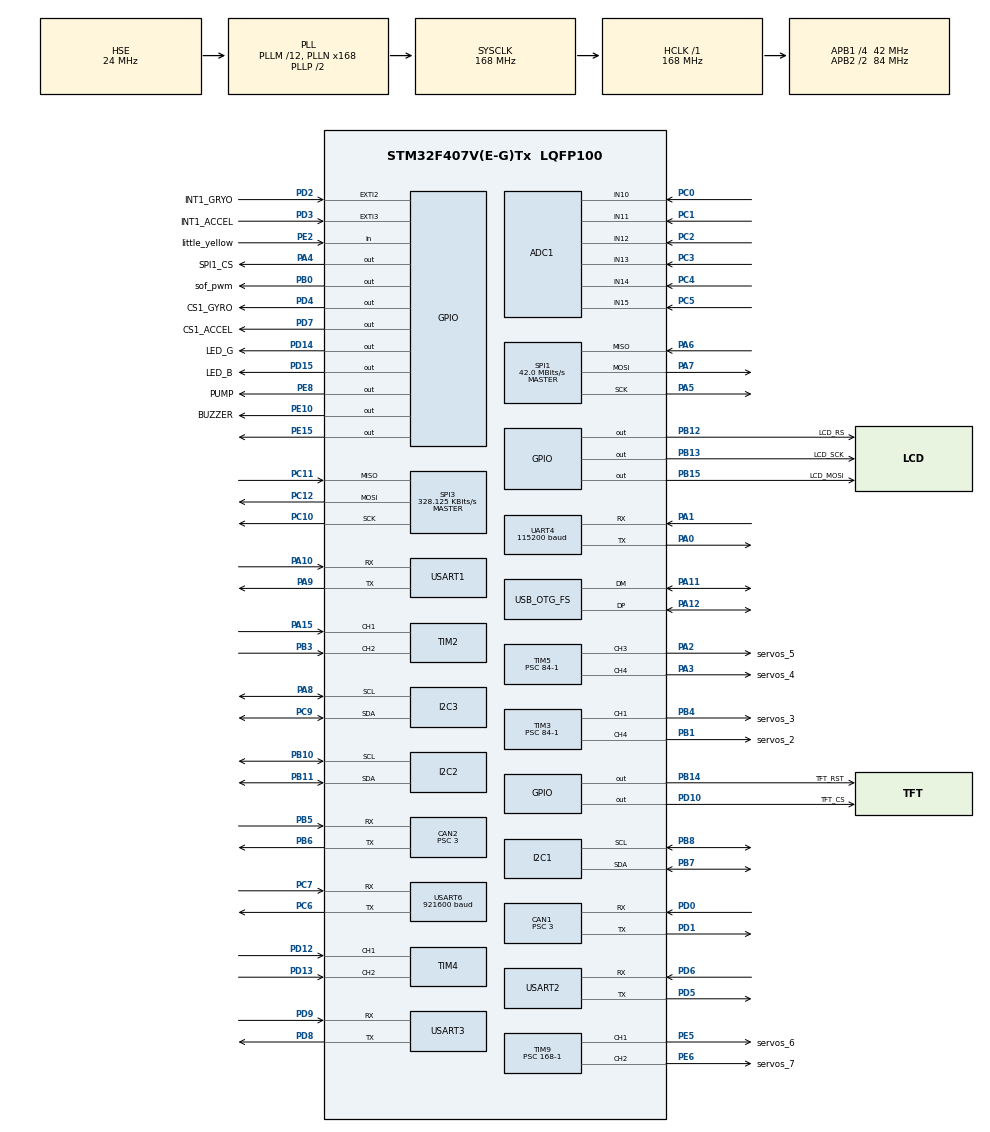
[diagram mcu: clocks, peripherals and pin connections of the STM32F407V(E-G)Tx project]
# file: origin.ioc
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ADC1.Channel-0\#ChannelRegularConversion=ADC_CHANNEL_10
ADC1.ClockPrescaler=ADC_CLOCK_SYNC_PCLK_DIV4
ADC1.NbrOfConversionFlag=1
ADC1.Rank-0\#ChannelRegularConversion=1
ADC1.SamplingTime-0\#ChannelRegularConversion=ADC_SAMPLETIME_3CYCLES
ADC1.master=1
ADC2.Channel-0\#ChannelRegularConversion=ADC_CHANNEL_10
ADC2.ClockPrescaler=ADC_CLOCK_SYNC_PCLK_DIV4
ADC2.NbrOfConversionFlag=1
ADC2.Rank-0\#ChannelRegularConversion=1
ADC2.SamplingTime-0\#ChannelRegularConversion=ADC_SAMPLETIME_3CYCLES
CAN1.BS1=CAN_BS1_10TQ
CAN1.BS2=CAN_BS2_3TQ
CAN1.CalculateBaudRate=1000000
CAN1.CalculateTimeBit=1000
CAN1.CalculateTimeQuantum=71.42857142857143
CAN1.Prescaler=3
CAN2.BS1=CAN_BS1_10TQ
CAN2.BS2=CAN_BS2_3TQ
CAN2.CalculateBaudRate=1000000
CAN2.CalculateTimeBit=1000
CAN2.CalculateTimeQuantum=71.42857142857143
CAN2.Prescaler=3
Dma.Request0=SPI3_RX
Dma.Request1=SPI3_TX
Dma.Request2=USART6_RX
Dma.Request3=USART6_TX
Dma.Request4=USART1_RX
Dma.Request5=USART1_TX
Dma.Request6=USART2_RX
Dma.Request7=USART2_TX
Dma.Request8=UART4_RX
Dma.Request9=UART4_TX
Dma.SPI3_RX.0.Direction=DMA_PERIPH_TO_MEMORY
Dma.SPI3_RX.0.FIFOMode=DMA_FIFOMODE_DISABLE
Dma.SPI3_RX.0.Instance=DMA1_Stream0
Dma.SPI3_RX.0.MemDataAlignment=DMA_MDATAALIGN_BYTE
Dma.SPI3_RX.0.MemInc=DMA_MINC_ENABLE
Dma.SPI3_RX.0.Mode=DMA_NORMAL
Dma.SPI3_RX.0.PeriphDataAlignment=DMA_PDATAALIGN_BYTE
Dma.SPI3_RX.0.PeriphInc=DMA_PINC_DISABLE
Dma.SPI3_RX.0.Priority=DMA_PRIORITY_HIGH
Dma.SPI3_TX.1.Direction=DMA_MEMORY_TO_PERIPH
Dma.SPI3_TX.1.FIFOMode=DMA_FIFOMODE_DISABLE
Dma.SPI3_TX.1.Instance=DMA1_Stream7
Dma.SPI3_TX.1.MemDataAlignment=DMA_MDATAALIGN_BYTE
Dma.SPI3_TX.1.MemInc=DMA_MINC_ENABLE
Dma.SPI3_TX.1.Mode=DMA_NORMAL
Dma.SPI3_TX.1.PeriphDataAlignment=DMA_PDATAALIGN_BYTE
Dma.SPI3_TX.1.PeriphInc=DMA_PINC_DISABLE
Dma.SPI3_TX.1.Priority=DMA_PRIORITY_MEDIUM
Dma.UART4_RX.8.Direction=DMA_PERIPH_TO_MEMORY
Dma.UART4_RX.8.FIFOMode=DMA_FIFOMODE_DISABLE
Dma.UART4_RX.8.Instance=DMA1_Stream2
Dma.UART4_RX.8.MemDataAlignment=DMA_MDATAALIGN_BYTE
Dma.UART4_RX.8.MemInc=DMA_MINC_ENABLE
Dma.UART4_RX.8.Mode=DMA_NORMAL
Dma.UART4_RX.8.PeriphDataAlignment=DMA_PDATAALIGN_BYTE
Dma.UART4_RX.8.PeriphInc=DMA_PINC_DISABLE
Dma.UART4_RX.8.Priority=DMA_PRIORITY_LOW
Dma.UART4_TX.9.Direction=DMA_MEMORY_TO_PERIPH
Dma.UART4_TX.9.FIFOMode=DMA_FIFOMODE_DISABLE
Dma.UART4_TX.9.Instance=DMA1_Stream4
Dma.UART4_TX.9.MemDataAlignment=DMA_MDATAALIGN_BYTE
Dma.UART4_TX.9.MemInc=DMA_MINC_ENABLE
Dma.UART4_TX.9.Mode=DMA_NORMAL
Dma.UART4_TX.9.PeriphDataAlignment=DMA_PDATAALIGN_BYTE
Dma.UART4_TX.9.PeriphInc=DMA_PINC_DISABLE
Dma.UART4_TX.9.Priority=DMA_PRIORITY_LOW
Dma.USART1_RX.4.Direction=DMA_PERIPH_TO_MEMORY
Dma.USART1_RX.4.FIFOMode=DMA_FIFOMODE_DISABLE
Dma.USART1_RX.4.Instance=DMA2_Stream2
Dma.USART1_RX.4.MemDataAlignment=DMA_MDATAALIGN_BYTE
Dma.USART1_RX.4.MemInc=DMA_MINC_ENABLE
Dma.USART1_RX.4.Mode=DMA_NORMAL
Dma.USART1_RX.4.PeriphDataAlignment=DMA_PDATAALIGN_BYTE
Dma.USART1_RX.4.PeriphInc=DMA_PINC_DISABLE
Dma.USART1_RX.4.Priority=DMA_PRIORITY_LOW
Dma.USART1_TX.5.Direction=DMA_MEMORY_TO_PERIPH
Dma.USART1_TX.5.FIFOMode=DMA_FIFOMODE_DISABLE
Dma.USART1_TX.5.Instance=DMA2_Stream7
Dma.USART1_TX.5.MemDataAlignment=DMA_MDATAALIGN_BYTE
Dma.USART1_TX.5.MemInc=DMA_MINC_ENABLE
Dma.USART1_TX.5.Mode=DMA_NORMAL
Dma.USART1_TX.5.PeriphDataAlignment=DMA_PDATAALIGN_BYTE
Dma.USART1_TX.5.PeriphInc=DMA_PINC_DISABLE
Dma.USART1_TX.5.Priority=DMA_PRIORITY_LOW
Dma.USART2_RX.6.Direction=DMA_PERIPH_TO_MEMORY
Dma.USART2_RX.6.FIFOMode=DMA_FIFOMODE_DISABLE
Dma.USART2_RX.6.Instance=DMA1_Stream5
Dma.USART2_RX.6.MemDataAlignment=DMA_MDATAALIGN_BYTE
Dma.USART2_RX.6.MemInc=DMA_MINC_ENABLE
Dma.USART2_RX.6.Mode=DMA_NORMAL
Dma.USART2_RX.6.PeriphDataAlignment=DMA_PDATAALIGN_BYTE
Dma.USART2_RX.6.PeriphInc=DMA_PINC_DISABLE
Dma.USART2_RX.6.Priority=DMA_PRIORITY_LOW
Dma.USART2_TX.7.Direction=DMA_MEMORY_TO_PERIPH
Dma.USART2_TX.7.FIFOMode=DMA_FIFOMODE_DISABLE
Dma.USART2_TX.7.Instance=DMA1_Stream6
Dma.USART2_TX.7.MemDataAlignment=DMA_MDATAALIGN_BYTE
Dma.USART2_TX.7.MemInc=DMA_MINC_ENABLE
Dma.USART2_TX.7.Mode=DMA_NORMAL
Dma.USART2_TX.7.PeriphDataAlignment=DMA_PDATAALIGN_BYTE
Dma.USART2_TX.7.PeriphInc=DMA_PINC_DISABLE
Dma.USART2_TX.7.Priority=DMA_PRIORITY_LOW
Dma.USART6_RX.2.Direction=DMA_PERIPH_TO_MEMORY
Dma.USART6_RX.2.FIFOMode=DMA_FIFOMODE_DISABLE
Dma.USART6_RX.2.Instance=DMA2_Stream1
Dma.USART6_RX.2.MemDataAlignment=DMA_MDATAALIGN_BYTE
Dma.USART6_RX.2.MemInc=DMA_MINC_ENABLE
Dma.USART6_RX.2.Mode=DMA_NORMAL
Dma.USART6_RX.2.PeriphDataAlignment=DMA_PDATAALIGN_BYTE
Dma.USART6_RX.2.PeriphInc=DMA_PINC_DISABLE
Dma.USART6_RX.2.Priority=DMA_PRIORITY_LOW
Dma.USART6_TX.3.Direction=DMA_MEMORY_TO_PERIPH
Dma.USART6_TX.3.FIFOMode=DMA_FIFOMODE_DISABLE
Dma.USART6_TX.3.Instance=DMA2_Stream6
Dma.USART6_TX.3.MemDataAlignment=DMA_MDATAALIGN_BYTE
Dma.USART6_TX.3.MemInc=DMA_MINC_ENABLE
Dma.USART6_TX.3.Mode=DMA_NORMAL
Dma.USART6_TX.3.PeriphDataAlignment=DMA_PDATAALIGN_BYTE
Dma.USART6_TX.3.PeriphInc=DMA_PINC_DISABLE
Dma.USART6_TX.3.Priority=DMA_PRIORITY_LOW
FREERTOS.Tasks01=defaultTask,0,128,StartDefaultTask,Default,NULL,Dynamic,NULL,NULL
FREERTOS.configENABLE_FPU=1
Mcu.Family=STM32F4
Mcu.Name=STM32F407V(E-G)Tx
Mcu.Package=LQFP100
NVIC.DMA1_Stream0_IRQn=true\:5\:0\:false\:false\:true\:true\:false\:true\:true
NVIC.DMA1_Stream2_IRQn=true\:5\:0\:false\:false\:true\:true\:false\:true\:true
NVIC.DMA1_Stream4_IRQn=true\:5\:0\:false\:false\:true\:true\:false\:true\:true
NVIC.DMA1_Stream5_IRQn=true\:5\:0\:false\:false\:true\:true\:false\:true\:true
NVIC.DMA1_Stream6_IRQn=true\:5\:0\:false\:false\:true\:true\:false\:true\:true
NVIC.DMA1_Stream7_IRQn=true\:5\:0\:false\:false\:true\:false\:false\:true\:true
NVIC.DMA2_Stream1_IRQn=true\:5\:0\:false\:false\:true\:true\:false\:true\:true
NVIC.DMA2_Stream2_IRQn=true\:5\:0\:false\:false\:true\:true\:false\:true\:true
NVIC.DMA2_Stream6_IRQn=true\:5\:0\:false\:false\:true\:true\:false\:true\:true
NVIC.DMA2_Stream7_IRQn=true\:5\:0\:false\:false\:true\:true\:false\:true\:true
NVIC.EXTI2_IRQn=true\:5\:0\:true\:false\:true\:true\:true\:true\:true
NVIC.EXTI3_IRQn=true\:5\:0\:true\:false\:true\:true\:true\:true\:true
NVIC.PriorityGroup=NVIC_PRIORITYGROUP_4
NVIC.TIM8_UP_TIM13_IRQn=true\:5\:0\:false\:false\:true\:true\:true\:true\:true
NVIC.UART4_IRQn=true\:5\:0\:false\:false\:true\:true\:true\:true\:true
NVIC.USART1_IRQn=true\:5\:0\:false\:false\:true\:true\:true\:true\:true
NVIC.USART2_IRQn=true\:5\:0\:false\:false\:true\:true\:true\:true\:true
NVIC.USART6_IRQn=true\:5\:0\:false\:false\:true\:true\:true\:true\:true
PA0-WKUP.Mode=Asynchronous
PA0-WKUP.Signal=UART4_TX
PA1.Mode=Asynchronous
PA1.Signal=UART4_RX
PA10.Mode=Asynchronous
PA10.Signal=USART1_RX
PA11.Mode=Device_Only
PA11.Signal=USB_OTG_FS_DM
PA12.Mode=Device_Only
PA12.Signal=USB_OTG_FS_DP
PA13.Mode=Serial_Wire
PA13.Signal=SYS_JTMS-SWDIO
PA14.Mode=Serial_Wire
PA14.Signal=SYS_JTCK-SWCLK
PA15.Signal=S_TIM2_CH1_ETR
PA2.GPIO_Label=servos_5
PA2.Signal=S_TIM5_CH3
PA3.GPIO_Label=servos_4
PA3.Signal=S_TIM5_CH4
PA4.GPIO_Label=SPI1_CS
PA4.Signal=GPIO_Output
PA5.Mode=Full_Duplex_Master
PA5.Signal=SPI1_SCK
PA6.Mode=Full_Duplex_Master
PA6.Signal=SPI1_MISO
PA7.Mode=Full_Duplex_Master
PA7.Signal=SPI1_MOSI
PA8.Mode=I2C
PA8.Signal=I2C3_SCL
PA9.Mode=Asynchronous
PA9.Signal=USART1_TX
PB0.GPIO_Label=sof_pwm
PB0.Signal=GPIO_Output
PB1.GPIO_Label=servos_2
PB1.Signal=S_TIM3_CH4
PB10.Mode=I2C
PB10.Signal=I2C2_SCL
PB11.Mode=I2C
PB11.Signal=I2C2_SDA
PB12.GPIO_Label=LCD_RS
PB12.GPIO_Speed=GPIO_SPEED_FREQ_HIGH
PB12.PinState=GPIO_PIN_SET
PB12.Signal=GPIO_Output
PB13.GPIO_Label=LCD_SCK
PB13.GPIO_PuPd=GPIO_PULLUP
PB13.GPIO_Speed=GPIO_SPEED_FREQ_HIGH
PB13.PinState=GPIO_PIN_SET
PB13.Signal=GPIO_Output
PB14.GPIO_Label=TFT_RST
PB14.GPIO_PuPd=GPIO_PULLUP
PB14.GPIO_Speed=GPIO_SPEED_FREQ_HIGH
PB14.PinState=GPIO_PIN_SET
PB14.Signal=GPIO_Output
PB15.GPIO_Label=LCD_MOSI
PB15.GPIO_PuPd=GPIO_PULLUP
PB15.GPIO_Speed=GPIO_SPEED_FREQ_HIGH
PB15.PinState=GPIO_PIN_SET
PB15.Signal=GPIO_Output
PB3.Signal=S_TIM2_CH2
PB4.GPIO_Label=servos_3
PB4.Signal=S_TIM3_CH1
PB5.Mode=CAN_Activate
PB5.Signal=CAN2_RX
PB6.Mode=CAN_Activate
PB6.Signal=CAN2_TX
PB7.Mode=I2C
PB7.Signal=I2C1_SDA
PB8.Mode=I2C
PB8.Signal=I2C1_SCL
PC0.Signal=ADCx_IN10
PC1.Signal=ADCx_IN11
PC10.Mode=Full_Duplex_Master
PC10.Signal=SPI3_SCK
PC11.Mode=Full_Duplex_Master
PC11.Signal=SPI3_MISO
PC12.Mode=Full_Duplex_Master
PC12.Signal=SPI3_MOSI
PC2.Signal=ADCx_IN12
PC3.Signal=ADCx_IN13
PC4.Signal=ADCx_IN14
PC5.Signal=ADCx_IN15
PC6.Mode=Asynchronous
PC6.Signal=USART6_TX
PC7.Mode=Asynchronous
PC7.Signal=USART6_RX
PC9.Mode=I2C
PC9.Signal=I2C3_SDA
PD0.Mode=CAN_Activate
PD0.Signal=CAN1_RX
PD1.Mode=CAN_Activate
PD1.Signal=CAN1_TX
PD10.GPIO_Label=TFT_CS
PD10.GPIO_Speed=GPIO_SPEED_FREQ_HIGH
PD10.PinState=GPIO_PIN_SET
PD10.Signal=GPIO_Output
PD12.Signal=S_TIM4_CH1
PD13.Signal=S_TIM4_CH2
PD14.GPIO_Label=LED_G
PD14.GPIO_PuPd=GPIO_NOPULL
PD14.Signal=GPIO_Output
PD15.GPIO_Label=LED_B
PD15.Signal=GPIO_Output
PD2.GPIO_Label=INT1_GRYO
PD2.GPIO_PuPd=GPIO_PULLUP
PD2.Signal=GPXTI2
PD3.GPIO_Label=INT1_ACCEL
PD3.GPIO_PuPd=GPIO_PULLUP
PD3.Signal=GPXTI3
PD4.GPIO_Label=CS1_GYRO
PD4.GPIO_PuPd=GPIO_PULLUP
PD4.GPIO_Speed=GPIO_SPEED_FREQ_HIGH
PD4.PinState=GPIO_PIN_SET
PD4.Signal=GPIO_Output
PD5.Mode=Asynchronous
PD5.Signal=USART2_TX
PD6.Mode=Asynchronous
PD6.Signal=USART2_RX
PD7.GPIO_Label=CS1_ACCEL
PD7.GPIO_PuPd=GPIO_PULLUP
PD7.GPIO_Speed=GPIO_SPEED_FREQ_HIGH
PD7.PinState=GPIO_PIN_SET
PD7.Signal=GPIO_Output
PD8.Mode=Asynchronous
PD8.Signal=USART3_TX
PD9.Mode=Asynchronous
PD9.Signal=USART3_RX
PE10.GPIO_Label=BUZZER
PE10.GPIO_PuPd=GPIO_PULLUP
PE10.Signal=GPIO_Output
PE15.Signal=GPIO_Output
PE2.GPIO_Label=little_yellow
PE2.Signal=GPIO_Input
PE5.GPIO_Label=servos_6
PE5.Signal=S_TIM9_CH1
PE6.GPIO_Label=servos_7
PE6.Signal=S_TIM9_CH2
PE8.GPIO_Label=PUMP
PE8.Signal=GPIO_Output
PH0-OSC_IN.Mode=HSE-External-Oscillator
PH0-OSC_IN.Signal=RCC_OSC_IN
PH1-OSC_OUT.Mode=HSE-External-Oscillator
PH1-OSC_OUT.Signal=RCC_OSC_OUT
ProjectManager.HeapSize=0x2000
ProjectManager.StackSize=0x1000
ProjectManager.TargetToolchain=MDK-ARM V5.32
RCC.48MHZClocksFreq_Value=48000000
RCC.AHBFreq_Value=168000000
RCC.APB1CLKDivider=RCC_HCLK_DIV4
RCC.APB1Freq_Value=42000000
RCC.APB1TimFreq_Value=84000000
RCC.APB2CLKDivider=RCC_HCLK_DIV2
RCC.APB2Freq_Value=84000000
RCC.APB2TimFreq_Value=168000000
RCC.CortexFreq_Value=168000000
RCC.HCLKFreq_Value=168000000
RCC.HSE_VALUE=24000000
RCC.HSI_VALUE=16000000
RCC.LSE_VALUE=32768
RCC.PLLM=12
RCC.PLLN=168
RCC.PLLQ=7
RCC.SYSCLKFreq_VALUE=168000000
RCC.SYSCLKSource=RCC_SYSCLKSOURCE_PLLCLK
RCC.VCOOutputFreq_Value=336000000
SH.ADCx_IN10.0=ADC1_IN10,IN10
SH.ADCx_IN10.1=ADC2_IN10,IN10
SH.ADCx_IN11.0=ADC1_IN11,IN11
SH.ADCx_IN11.1=ADC2_IN11,IN11
SH.ADCx_IN12.0=ADC1_IN12,IN12
SH.ADCx_IN12.1=ADC2_IN12,IN12
SH.ADCx_IN13.0=ADC1_IN13,IN13
SH.ADCx_IN13.1=ADC2_IN13,IN13
SH.ADCx_IN14.0=ADC1_IN14,IN14
SH.ADCx_IN14.1=ADC2_IN14,IN14
SH.ADCx_IN15.0=ADC1_IN15,IN15
SH.ADCx_IN15.1=ADC2_IN15,IN15
SH.S_TIM2_CH1_ETR.0=TIM2_CH1,Encoder_Interface
SH.S_TIM2_CH2.0=TIM2_CH2,Encoder_Interface
SH.S_TIM3_CH1.0=TIM3_CH1,PWM Generation1 CH1
SH.S_TIM3_CH4.0=TIM3_CH4,PWM Generation4 CH4
SH.S_TIM4_CH1.0=TIM4_CH1,Encoder_Interface
SH.S_TIM4_CH2.0=TIM4_CH2,Encoder_Interface
SH.S_TIM5_CH3.0=TIM5_CH3,PWM Generation3 CH3
SH.S_TIM5_CH4.0=TIM5_CH4,PWM Generation4 CH4
SH.S_TIM9_CH1.0=TIM9_CH1,PWM Generation1 CH1
SH.S_TIM9_CH2.0=TIM9_CH2,PWM Generation2 CH2
SPI1.CalculateBaudRate=42.0 MBits/s
SPI1.Direction=SPI_DIRECTION_2LINES
SPI1.Mode=SPI_MODE_MASTER
SPI1.VirtualType=VM_MASTER
SPI3.BaudRatePrescaler=SPI_BAUDRATEPRESCALER_128
SPI3.CLKPhase=SPI_PHASE_2EDGE
SPI3.CLKPolarity=SPI_POLARITY_HIGH
SPI3.CalculateBaudRate=328.125 KBits/s
SPI3.Direction=SPI_DIRECTION_2LINES
SPI3.Mode=SPI_MODE_MASTER
SPI3.VirtualType=VM_MASTER
TIM13.AutoReloadPreload=TIM_AUTORELOAD_PRELOAD_ENABLE
TIM13.Period=100-1
TIM13.Prescaler=84-1
TIM3.AutoReloadPreload=TIM_AUTORELOAD_PRELOAD_ENABLE
TIM3.Channel-PWM\ Generation1\ CH1=TIM_CHANNEL_1
TIM3.Channel-PWM\ Generation4\ CH4=TIM_CHANNEL_4
TIM3.Period=20000-1
TIM3.Prescaler=84-1
TIM5.AutoReloadPreload=TIM_AUTORELOAD_PRELOAD_ENABLE
TIM5.Channel-PWM\ Generation3\ CH3=TIM_CHANNEL_3
TIM5.Channel-PWM\ Generation4\ CH4=TIM_CHANNEL_4
TIM5.Period=20000-1
TIM5.Prescaler=84-1
TIM9.AutoReloadPreload=TIM_AUTORELOAD_PRELOAD_ENABLE
TIM9.Channel-PWM\ Generation1\ CH1=TIM_CHANNEL_1
TIM9.Channel-PWM\ Generation2\ CH2=TIM_CHANNEL_2
TIM9.Period=20000-1
TIM9.Prescaler=168-1
UART4.BaudRate=115200
UART4.VirtualMode=Asynchronous
USART1.VirtualMode=VM_ASYNC
USART2.VirtualMode=VM_ASYNC
USART3.VirtualMode=VM_ASYNC
USART6.BaudRate=921600
USART6.VirtualMode=VM_ASYNC
USB_OTG_FS.VirtualMode=Device_Only
VP_FREERTOS_VS_CMSIS_V1.Mode=CMSIS_V1
VP_TIM13_VS_ClockSourceINT.Mode=Enable_Timer
VP_TIM3_VS_ClockSourceINT.Mode=Internal
VP_TIM5_VS_ClockSourceINT.Mode=Internal
VP_TIM9_VS_ClockSourceINT.Mode=Internal
board=custom

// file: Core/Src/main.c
/* USER CODE BEGIN Header */
/**
 ******************************************************************************
 * @file           : main.c
 * @brief          : Main program body
 ******************************************************************************
 * @attention
 *
 * Copyright (c) 2025 STMicroelectronics.
 * All rights reserved.
 *
 * This software is licensed under terms that can be found in the LICENSE file
 * in the root directory of this software component.
 * If no LICENSE file comes with this software, it is provided AS-IS.
 *
 ******************************************************************************
 */
/* USER CODE END Header */
#include "main.h"
#include "cmsis_os.h"
#include "adc.h"
#include "can.h"
#include "dma.h"
#include "i2c.h"
#include "spi.h"
#include "tim.h"
#include "usart.h"
#include "usb_otg.h"
#include "gpio.h"

/* USER CODE BEGIN Includes */
#include "dm_j4310.h"
#include "ZDTstepmotor.h"
#include "mainwork.h"

/* USER CODE END Includes */

void SystemClock_Config(void);
void MX_FREERTOS_Init(void);

int main(void)
{

  /* MCU Configuration--------------------------------------------------------*/

  /* Reset of all peripherals, Initializes the Flash interface and the Systick. */
  HAL_Init();

  /* Configure the system clock */
  SystemClock_Config();

  /* Initialize all configured peripherals */
  MX_GPIO_Init();
  MX_DMA_Init();
  MX_CAN1_Init();
  MX_SPI1_Init();
  MX_ADC1_Init();
  MX_ADC2_Init();
  MX_CAN2_Init();
  MX_I2C1_Init();
  MX_I2C2_Init();
  MX_I2C3_Init();
  MX_SPI3_Init();
  MX_TIM2_Init();
  MX_TIM3_Init();
  MX_TIM4_Init();
  MX_TIM5_Init();
  MX_TIM9_Init();
  MX_UART4_Init();
  MX_USART1_UART_Init();
  MX_USART2_UART_Init();
  MX_USART3_UART_Init();
  MX_USART6_UART_Init();
  MX_USB_OTG_FS_PCD_Init();
  MX_TIM13_Init();
  /* USER CODE BEGIN 2 */
	HAL_TIM_Base_Start_IT(&htim13);
  HAL_GPIO_WritePin(GPIOD, GPIO_PIN_14, 0);
  HAL_GPIO_WritePin(GPIOD, GPIO_PIN_15, 0);
	//pwm配置
	HAL_TIM_PWM_Start(&htim3,TIM_CHANNEL_1);
	HAL_TIM_PWM_Start(&htim3,TIM_CHANNEL_4);
	HAL_TIM_PWM_Start(&htim5,TIM_CHANNEL_4);
	HAL_TIM_PWM_Start(&htim5,TIM_CHANNEL_3);
	HAL_TIM_PWM_Start(&htim9,TIM_CHANNEL_1);
	HAL_TIM_PWM_Start(&htim9,TIM_CHANNEL_2);

//  HAL_Delay(4000);
	//这时候板子的pwm还是上一版

  main_work();

  /* USER CODE END 2 */

  /* Call init function for freertos objects (in cmsis_os2.c) */
  MX_FREERTOS_Init();

  /* Start scheduler */
  osKernelStart();

  /* We should never get here as control is now taken by the scheduler */

  /* Infinite loop */
  while (1)
  {

  }
}

void SystemClock_Config(void)
{
  RCC_OscInitTypeDef RCC_OscInitStruct = {0};
  RCC_ClkInitTypeDef RCC_ClkInitStruct = {0};

  /** Configure the main internal regulator output voltage
  */
  __HAL_RCC_PWR_CLK_ENABLE();
  __HAL_PWR_VOLTAGESCALING_CONFIG(PWR_REGULATOR_VOLTAGE_SCALE1);

  /** Initializes the RCC Oscillators according to the specified parameters
  * in the RCC_OscInitTypeDef structure.
  */
  RCC_OscInitStruct.OscillatorType = RCC_OSCILLATORTYPE_HSE;
  RCC_OscInitStruct.HSEState = RCC_HSE_ON;
  RCC_OscInitStruct.PLL.PLLState = RCC_PLL_ON;
  RCC_OscInitStruct.PLL.PLLSource = RCC_PLLSOURCE_HSE;
  RCC_OscInitStruct.PLL.PLLM = 12;
  RCC_OscInitStruct.PLL.PLLN = 168;
  RCC_OscInitStruct.PLL.PLLP = RCC_PLLP_DIV2;
  RCC_OscInitStruct.PLL.PLLQ = 7;
  if (HAL_RCC_OscConfig(&RCC_OscInitStruct) != HAL_OK)
  {
    Error_Handler();
  }

  /** Initializes the CPU, AHB and APB buses clocks
  */
  RCC_ClkInitStruct.ClockType = RCC_CLOCKTYPE_HCLK|RCC_CLOCKTYPE_SYSCLK
                              |RCC_CLOCKTYPE_PCLK1|RCC_CLOCKTYPE_PCLK2;
  RCC_ClkInitStruct.SYSCLKSource = RCC_SYSCLKSOURCE_PLLCLK;
  RCC_ClkInitStruct.AHBCLKDivider = RCC_SYSCLK_DIV1;
  RCC_ClkInitStruct.APB1CLKDivider = RCC_HCLK_DIV4;
  RCC_ClkInitStruct.APB2CLKDivider = RCC_HCLK_DIV2;

  if (HAL_RCC_ClockConfig(&RCC_ClkInitStruct, FLASH_LATENCY_5) != HAL_OK)
  {
    Error_Handler();
  }
}

void Error_Handler(void)
{
  __disable_irq();
  while (1)
  {
  }
}
